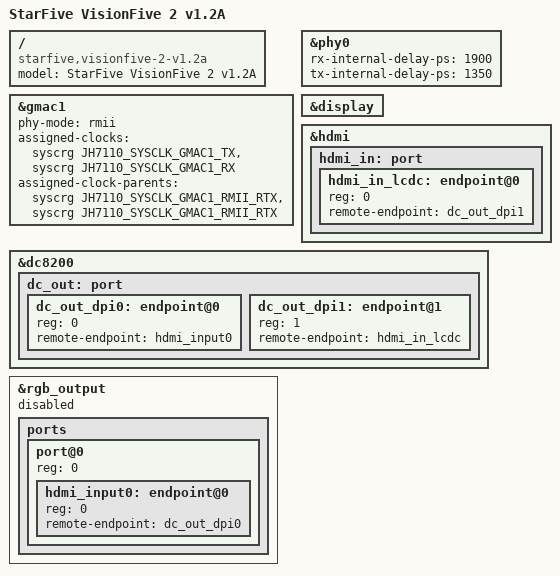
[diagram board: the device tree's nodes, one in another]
// SPDX-License-Identifier: GPL-2.0 OR MIT
/*
 * Copyright (C) 2022 StarFive Technology Co., Ltd.
 * Copyright (C) 2022 Emil Renner Berthing <kernel@esmil.dk>
 */

/dts-v1/;
#include "jh7110-starfive-visionfive-2.dtsi"

/ {
	model = "StarFive VisionFive 2 v1.2A";
	compatible = "starfive,visionfive-2-v1.2a", "starfive,jh7110";
};

&gmac1 {
	phy-mode = "rmii";
	assigned-clocks = <&syscrg JH7110_SYSCLK_GMAC1_TX>,
			  <&syscrg JH7110_SYSCLK_GMAC1_RX>;
	assigned-clock-parents = <&syscrg JH7110_SYSCLK_GMAC1_RMII_RTX>,
				 <&syscrg JH7110_SYSCLK_GMAC1_RMII_RTX>;
};

&phy0 {
	rx-internal-delay-ps = <1900>;
	tx-internal-delay-ps = <1350>;
};

&display {
	status = "okay";
};

&hdmi {
	status = "okay";
	pinctrl-names = "default";

	hdmi_in: port {
		#address-cells = <1>;
		#size-cells = <0>;
		hdmi_in_lcdc: endpoint@0 {
			reg = <0>;
			remote-endpoint = <&dc_out_dpi1>;
		};
	};
};

&dc8200 {
	status = "okay";

	dc_out: port {
		#address-cells = <1>;
		#size-cells = <0>;
		dc_out_dpi0: endpoint@0 {
			reg = <0>;
			remote-endpoint = <&hdmi_input0>;
		};
		dc_out_dpi1: endpoint@1 {
			reg = <1>;
			remote-endpoint = <&hdmi_in_lcdc>;
		};
		
	};
};

&rgb_output {
	status = "disabled";

	ports {
		#address-cells = <1>;
		#size-cells = <0>;
		port@0 {
			#address-cells = <1>;
			#size-cells = <0>;
			reg = <0>;
			hdmi_input0:endpoint@0 {
				reg = <0>;
				remote-endpoint = <&dc_out_dpi0>;
			};
		};
	};
};

